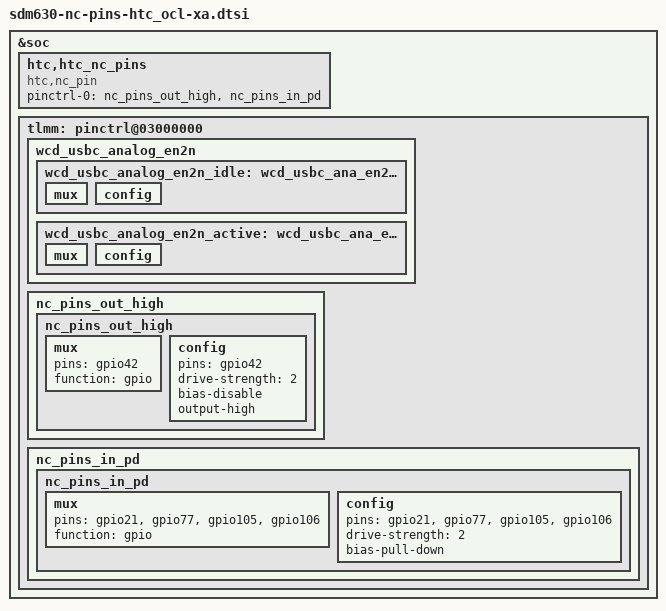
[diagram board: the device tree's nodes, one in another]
/* Copyright (c) 2016, The Linux Foundation. All rights reserved.
 *
 * This program is free software; you can redistribute it and/or modify
 * it under the terms of the GNU General Public License version 2 and
 * only version 2 as published by the Free Software Foundation.
 *
 * This program is distributed in the hope that it will be useful,
 * but WITHOUT ANY WARRANTY; without even the implied warranty of
 * MERCHANTABILITY or FITNESS FOR A PARTICULAR PURPOSE.  See the
 * GNU General Public License for more details.
 */

&soc {
	htc,htc_nc_pins {
		compatible = "htc,nc_pin";

		pinctrl-names = "default";
		pinctrl-0 = <&nc_pins_out_high &nc_pins_in_pd>;
	};
};

&tlmm {
	nc_pins_out_high {
		nc_pins_out_high: nc_pins_out_high {
			mux {
				/* gpio42: IO expander RST pin  */
				pins = "gpio42";
				function = "gpio";
			};

			config {
				pins = "gpio42";
				drive-strength = <2>;		/* 2 mA */
				bias-disable;
				output-high;			/* OUTPUT HIGH */
			};
		};
	};

	nc_pins_in_pd {
		nc_pins_in_pd: nc_pins_in_pd {
			mux {
				pins = "gpio21", "gpio77", "gpio105", "gpio106";
				function = "gpio";
			};

			config {
				pins = "gpio21", "gpio77", "gpio105", "gpio106";
				drive-strength = <2>;		/* 2 mA */
				bias-pull-down;			/* PULL DOWN */
			};
		};
	};
};

&soc {
	tlmm: pinctrl@03000000 {
		/* gpio77 */
			wcd_usbc_analog_en2n {
				wcd_usbc_analog_en2n_idle: wcd_usbc_ana_en2n_idle {
					mux {
						/delete-property/ pins;
					};

					config {
						/delete-property/ pins;
					};
				};

				wcd_usbc_analog_en2n_active: wcd_usbc_ana_en2n_active {
					mux {
						/delete-property/ pins;
					};

					config {
						/delete-property/ pins;
					};
				};
			};
	};
};
